# BL702 register map
Vendor: Bouffalo Lab; Series: WiFi BT; File version: 1.0
Registers are 32-bit, read-write, reset 0x0 unless marked. A register's access mark holds for its fields unless they carry their own. Offsets are from the block's base; [hi:lo] are bit positions; {n}, {i} and the like mark numbered series.

## MIX — RF mixed signal registers
Base 0x40001000
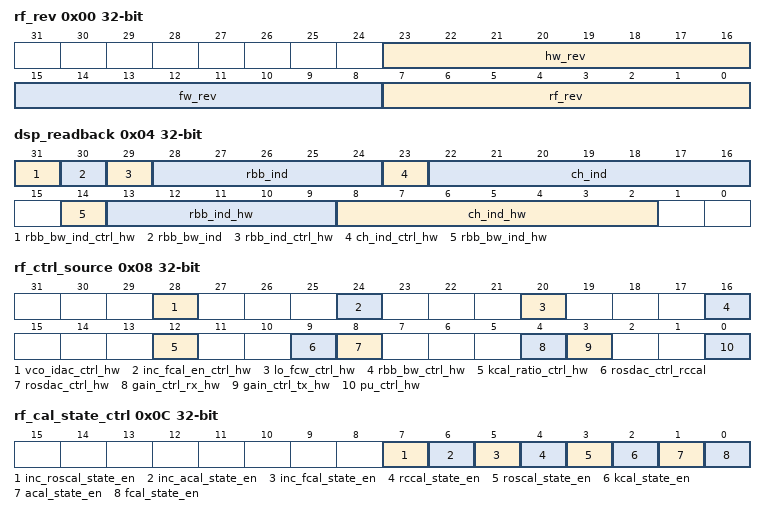
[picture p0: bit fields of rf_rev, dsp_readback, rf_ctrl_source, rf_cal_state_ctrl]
0x00 rf_rev — Silicon revision
  [23:16] hw_rev, [15:8] fw_rev, [7:0] rf_rev
0x04 dsp_readback
  [31] rbb_bw_ind_ctrl_hw, [30] rbb_bw_ind, [29] rbb_ind_ctrl_hw, [28:24] rbb_ind, [23] ch_ind_ctrl_hw, [22:16] ch_ind, [14] rbb_bw_ind_hw, [13:9] rbb_ind_hw, [8:2] ch_ind_hw
0x08 rf_ctrl_source — Control logic switch
  [28] vco_idac_ctrl_hw, [24] inc_fcal_en_ctrl_hw, [20] lo_fcw_ctrl_hw, [16] rbb_bw_ctrl_hw, [12] kcal_ratio_ctrl_hw, [9] rosdac_ctrl_rccal, [8] rosdac_ctrl_hw, [4] gain_ctrl_rx_hw, [3] gain_ctrl_tx_hw, [0] pu_ctrl_hw
0x0C rf_cal_state_ctrl — rf calibration state enable in full cal list
  [7] inc_roscal_state_en, [6] inc_acal_state_en, [5] inc_fcal_state_en, [4] rccal_state_en, [3] roscal_state_en, [2] kcal_state_en, [1] acal_state_en, [0] fcal_state_en
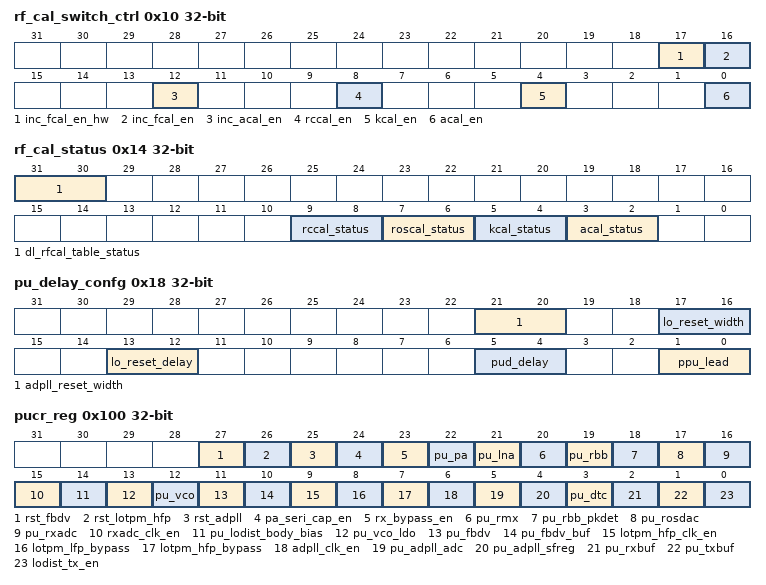
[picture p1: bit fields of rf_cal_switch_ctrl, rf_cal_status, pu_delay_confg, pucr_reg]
0x10 rf_cal_switch_ctrl — Calibration mode register
  [17] inc_fcal_en_hw, [16] inc_fcal_en, [12] inc_acal_en, [8] rccal_en, [4] kcal_en, [0] acal_en
0x14 rf_cal_status
  [31:30] dl_rfcal_table_status, [9:8] rccal_status, [7:6] roscal_status, [5:4] kcal_status, [3:2] acal_status
0x18 pu_delay_confg
  [21:20] adpll_reset_width, [17:16] lo_reset_width, [13:12] lo_reset_delay, [5:4] pud_delay, [1:0] ppu_lead
0x100 pucr_reg — Register control of power up signals
  [27] rst_fbdv, [26] rst_lotpm_hfp, [25] rst_adpll, [24] pa_seri_cap_en, [23] rx_bypass_en, [22] pu_pa, [21] pu_lna, [20] pu_rmx, [19] pu_rbb, [18] pu_rbb_pkdet, [17] pu_rosdac, [16] pu_rxadc, [15] rxadc_clk_en, [14] pu_lodist_body_bias, [13] pu_vco_ldo, [12] pu_vco, [11] pu_fbdv, [10] pu_fbdv_buf, [9] lotpm_hfp_clk_en, [8] lotpm_lfp_bypass, [7] lotpm_hfp_bypass, [6] adpll_clk_en, [5] pu_adpll_adc, [4] pu_adpll_sfreg, [3] pu_dtc, [2] pu_rxbuf, [1] pu_txbuf, [0] lodist_tx_en
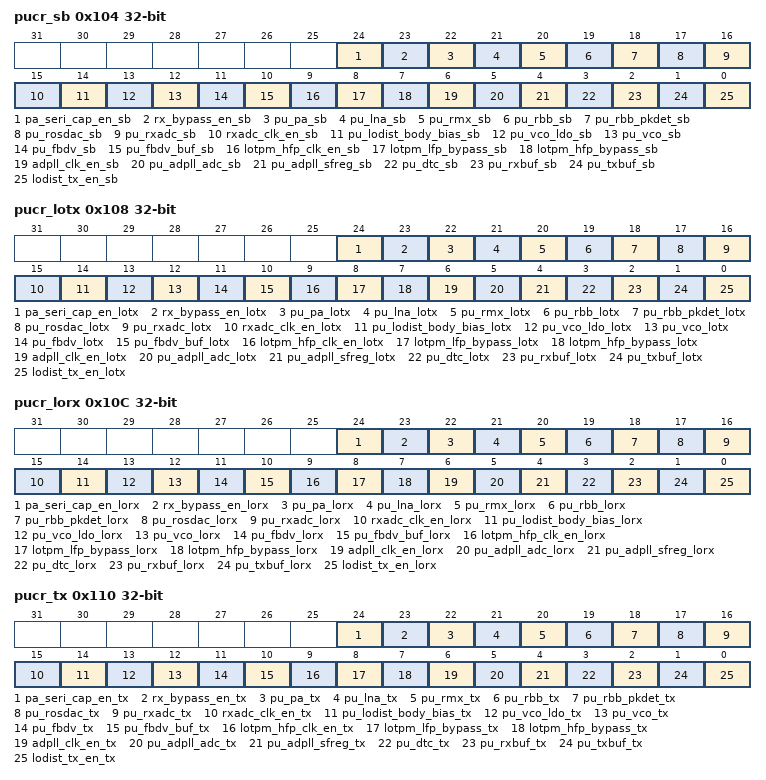
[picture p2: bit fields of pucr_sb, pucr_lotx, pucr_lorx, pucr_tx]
0x104 pucr_sb — Power up setting in SB state
  [24] pa_seri_cap_en_sb, [23] rx_bypass_en_sb, [22] pu_pa_sb, [21] pu_lna_sb, [20] pu_rmx_sb, [19] pu_rbb_sb, [18] pu_rbb_pkdet_sb, [17] pu_rosdac_sb, [16] pu_rxadc_sb, [15] rxadc_clk_en_sb, [14] pu_lodist_body_bias_sb, [13] pu_vco_ldo_sb, [12] pu_vco_sb, [11] pu_fbdv_sb, [10] pu_fbdv_buf_sb, [9] lotpm_hfp_clk_en_sb, [8] lotpm_lfp_bypass_sb, [7] lotpm_hfp_bypass_sb, [6] adpll_clk_en_sb, [5] pu_adpll_adc_sb, [4] pu_adpll_sfreg_sb, [3] pu_dtc_sb, [2] pu_rxbuf_sb, [1] pu_txbuf_sb, [0] lodist_tx_en_sb
0x108 pucr_lotx — Power up in LOTX state
  [24] pa_seri_cap_en_lotx, [23] rx_bypass_en_lotx, [22] pu_pa_lotx, [21] pu_lna_lotx, [20] pu_rmx_lotx, [19] pu_rbb_lotx, [18] pu_rbb_pkdet_lotx, [17] pu_rosdac_lotx, [16] pu_rxadc_lotx, [15] rxadc_clk_en_lotx, [14] pu_lodist_body_bias_lotx, [13] pu_vco_ldo_lotx, [12] pu_vco_lotx, [11] pu_fbdv_lotx, [10] pu_fbdv_buf_lotx, [9] lotpm_hfp_clk_en_lotx, [8] lotpm_lfp_bypass_lotx, [7] lotpm_hfp_bypass_lotx, [6] adpll_clk_en_lotx, [5] pu_adpll_adc_lotx, [4] pu_adpll_sfreg_lotx, [3] pu_dtc_lotx, [2] pu_rxbuf_lotx, [1] pu_txbuf_lotx, [0] lodist_tx_en_lotx
0x10C pucr_lorx — Power up in LORX state
  [24] pa_seri_cap_en_lorx, [23] rx_bypass_en_lorx, [22] pu_pa_lorx, [21] pu_lna_lorx, [20] pu_rmx_lorx, [19] pu_rbb_lorx, [18] pu_rbb_pkdet_lorx, [17] pu_rosdac_lorx, [16] pu_rxadc_lorx, [15] rxadc_clk_en_lorx, [14] pu_lodist_body_bias_lorx, [13] pu_vco_ldo_lorx, [12] pu_vco_lorx, [11] pu_fbdv_lorx, [10] pu_fbdv_buf_lorx, [9] lotpm_hfp_clk_en_lorx, [8] lotpm_lfp_bypass_lorx, [7] lotpm_hfp_bypass_lorx, [6] adpll_clk_en_lorx, [5] pu_adpll_adc_lorx, [4] pu_adpll_sfreg_lorx, [3] pu_dtc_lorx, [2] pu_rxbuf_lorx, [1] pu_txbuf_lorx, [0] lodist_tx_en_lorx
0x110 pucr_tx — Power up in TX state
  [24] pa_seri_cap_en_tx, [23] rx_bypass_en_tx, [22] pu_pa_tx, [21] pu_lna_tx, [20] pu_rmx_tx, [19] pu_rbb_tx, [18] pu_rbb_pkdet_tx, [17] pu_rosdac_tx, [16] pu_rxadc_tx, [15] rxadc_clk_en_tx, [14] pu_lodist_body_bias_tx, [13] pu_vco_ldo_tx, [12] pu_vco_tx, [11] pu_fbdv_tx, [10] pu_fbdv_buf_tx, [9] lotpm_hfp_clk_en_tx, [8] lotpm_lfp_bypass_tx, [7] lotpm_hfp_bypass_tx, [6] adpll_clk_en_tx, [5] pu_adpll_adc_tx, [4] pu_adpll_sfreg_tx, [3] pu_dtc_tx, [2] pu_rxbuf_tx, [1] pu_txbuf_tx, [0] lodist_tx_en_tx
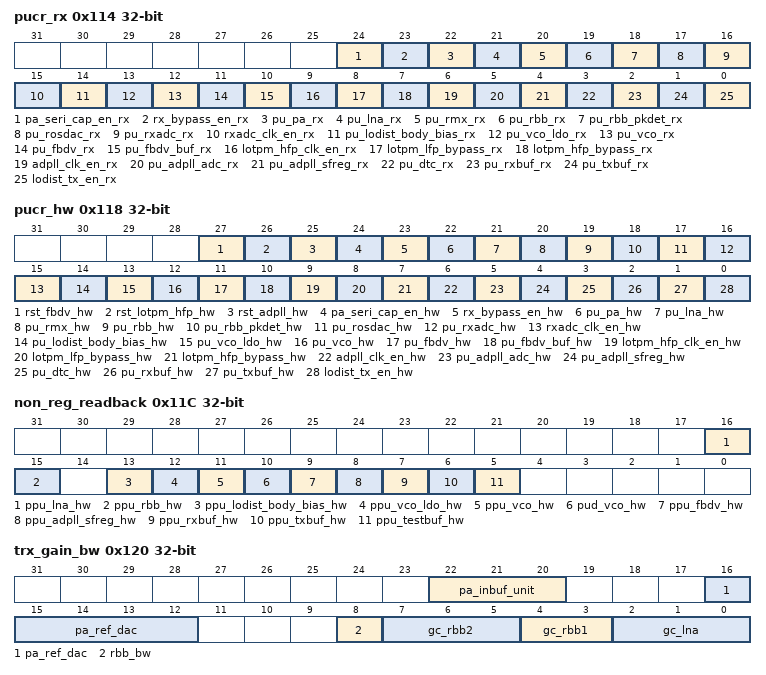
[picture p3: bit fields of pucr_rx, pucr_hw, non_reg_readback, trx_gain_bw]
0x114 pucr_rx — Power up in RX state
  [24] pa_seri_cap_en_rx, [23] rx_bypass_en_rx, [22] pu_pa_rx, [21] pu_lna_rx, [20] pu_rmx_rx, [19] pu_rbb_rx, [18] pu_rbb_pkdet_rx, [17] pu_rosdac_rx, [16] pu_rxadc_rx, [15] rxadc_clk_en_rx, [14] pu_lodist_body_bias_rx, [13] pu_vco_ldo_rx, [12] pu_vco_rx, [11] pu_fbdv_rx, [10] pu_fbdv_buf_rx, [9] lotpm_hfp_clk_en_rx, [8] lotpm_lfp_bypass_rx, [7] lotpm_hfp_bypass_rx, [6] adpll_clk_en_rx, [5] pu_adpll_adc_rx, [4] pu_adpll_sfreg_rx, [3] pu_dtc_rx, [2] pu_rxbuf_rx, [1] pu_txbuf_rx, [0] lodist_tx_en_rx
0x118 pucr_hw — Hardware read back of power up signals
  [27] rst_fbdv_hw, [26] rst_lotpm_hfp_hw, [25] rst_adpll_hw, [24] pa_seri_cap_en_hw, [23] rx_bypass_en_hw, [22] pu_pa_hw, [21] pu_lna_hw, [20] pu_rmx_hw, [19] pu_rbb_hw, [18] pu_rbb_pkdet_hw, [17] pu_rosdac_hw, [16] pu_rxadc_hw, [15] rxadc_clk_en_hw, [14] pu_lodist_body_bias_hw, [13] pu_vco_ldo_hw, [12] pu_vco_hw, [11] pu_fbdv_hw, [10] pu_fbdv_buf_hw, [9] lotpm_hfp_clk_en_hw, [8] lotpm_lfp_bypass_hw, [7] lotpm_hfp_bypass_hw, [6] adpll_clk_en_hw, [5] pu_adpll_adc_hw, [4] pu_adpll_sfreg_hw, [3] pu_dtc_hw, [2] pu_rxbuf_hw, [1] pu_txbuf_hw, [0] lodist_tx_en_hw
0x11C non_reg_readback
  [16] ppu_lna_hw, [15] ppu_rbb_hw, [13] ppu_lodist_body_bias_hw, [12] ppu_vco_ldo_hw, [11] ppu_vco_hw, [10] pud_vco_hw, [9] ppu_fbdv_hw, [8] ppu_adpll_sfreg_hw, [7] ppu_rxbuf_hw, [6] ppu_txbuf_hw, [5] ppu_testbuf_hw
0x120 trx_gain_bw — Register control of TX/RX gain
  [22:20] pa_inbuf_unit, [16:12] pa_ref_dac, [8] rbb_bw, [7:5] gc_rbb2, [4:3] gc_rbb1, [2:0] gc_lna
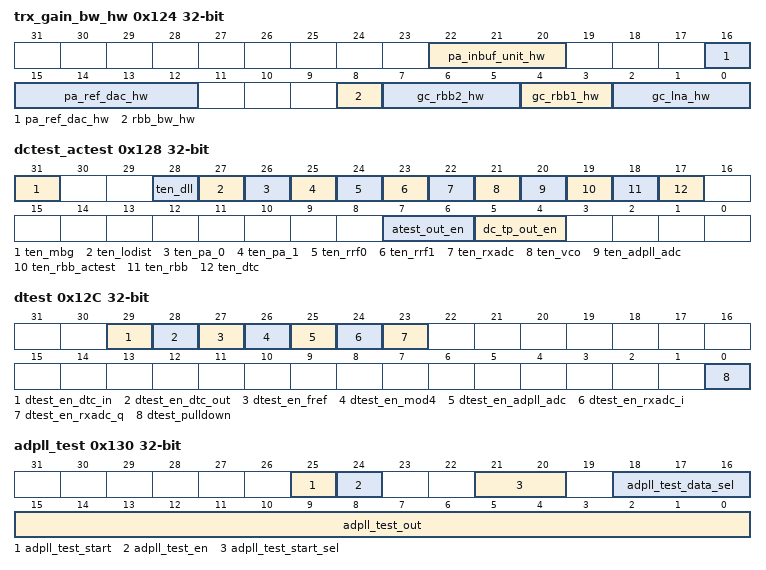
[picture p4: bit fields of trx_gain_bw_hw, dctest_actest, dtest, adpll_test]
0x124 trx_gain_bw_hw — Hardware read back of TX/RX gain
  [22:20] pa_inbuf_unit_hw, [16:12] pa_ref_dac_hw, [8] rbb_bw_hw, [7:5] gc_rbb2_hw, [4:3] gc_rbb1_hw, [2:0] gc_lna_hw
0x128 dctest_actest — DC Test register 0
  [31] ten_mbg, [28] ten_dll, [27] ten_lodist, [26] ten_pa_0, [25] ten_pa_1, [24] ten_rrf0, [23] ten_rrf1, [22] ten_rxadc, [21] ten_vco, [20] ten_adpll_adc, [19] ten_rbb_actest, [18] ten_rbb, [17] ten_dtc, [7:6] atest_out_en, [5:4] dc_tp_out_en
0x12C dtest — LO Bias Mode registers
  [29] dtest_en_dtc_in, [28] dtest_en_dtc_out, [27] dtest_en_fref, [26] dtest_en_mod4, [25] dtest_en_adpll_adc, [24] dtest_en_rxadc_i, [23] dtest_en_rxadc_q, [0] dtest_pulldown
0x130 adpll_test
  [25] adpll_test_start, [24] adpll_test_en, [21:20] adpll_test_start_sel, [18:16] adpll_test_data_sel, [15:0] adpll_test_out
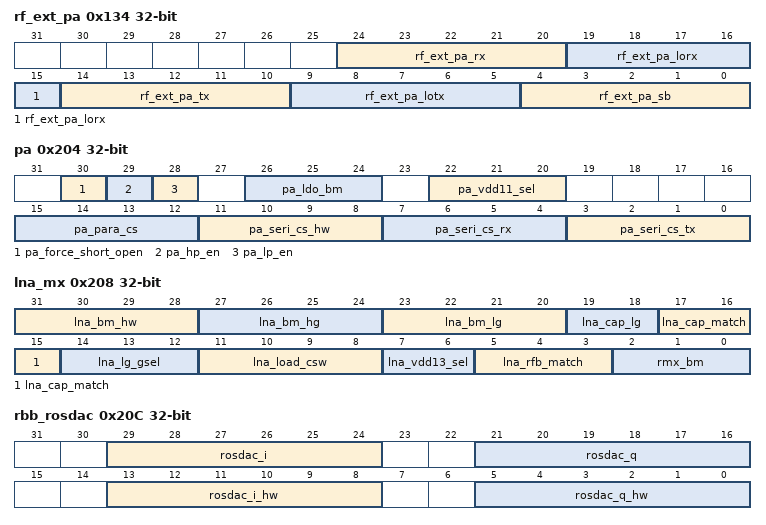
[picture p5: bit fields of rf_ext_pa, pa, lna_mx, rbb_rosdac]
0x134 rf_ext_pa
  [24:20] rf_ext_pa_rx, [19:15] rf_ext_pa_lorx, [14:10] rf_ext_pa_tx, [9:5] rf_ext_pa_lotx, [4:0] rf_ext_pa_sb
0x200 cip_ldo15
  [1:0] vg11_sel
0x204 pa
  [30] pa_force_short_open, [29] pa_hp_en, [28] pa_lp_en, [26:24] pa_ldo_bm, [22:20] pa_vdd11_sel, [15:12] pa_para_cs, [11:8] pa_seri_cs_hw, [7:4] pa_seri_cs_rx, [3:0] pa_seri_cs_tx
0x208 lna_mx — LNA mixer register
  [31:28] lna_bm_hw, [27:24] lna_bm_hg, [23:20] lna_bm_lg, [19:18] lna_cap_lg, [17:15] lna_cap_match, [14:12] lna_lg_gsel, [11:8] lna_load_csw, [7:6] lna_vdd13_sel, [5:3] lna_rfb_match, [2:0] rmx_bm
0x20C rbb_rosdac
  [29:24] rosdac_i, [21:16] rosdac_q, [13:8] rosdac_i_hw, [5:0] rosdac_q_hw
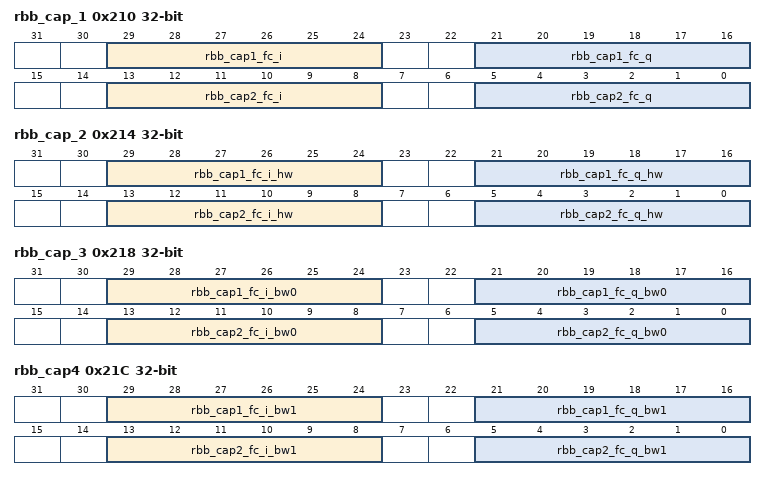
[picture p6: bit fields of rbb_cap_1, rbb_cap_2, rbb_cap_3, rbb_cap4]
0x210 rbb_cap_1
  [29:24] rbb_cap1_fc_i, [21:16] rbb_cap1_fc_q, [13:8] rbb_cap2_fc_i, [5:0] rbb_cap2_fc_q
0x214 rbb_cap_2
  [29:24] rbb_cap1_fc_i_hw, [21:16] rbb_cap1_fc_q_hw, [13:8] rbb_cap2_fc_i_hw, [5:0] rbb_cap2_fc_q_hw
0x218 rbb_cap_3
  [29:24] rbb_cap1_fc_i_bw0, [21:16] rbb_cap1_fc_q_bw0, [13:8] rbb_cap2_fc_i_bw0, [5:0] rbb_cap2_fc_q_bw0
0x21C rbb_cap4
  [29:24] rbb_cap1_fc_i_bw1, [21:16] rbb_cap1_fc_q_bw1, [13:8] rbb_cap2_fc_i_bw1, [5:0] rbb_cap2_fc_q_bw1
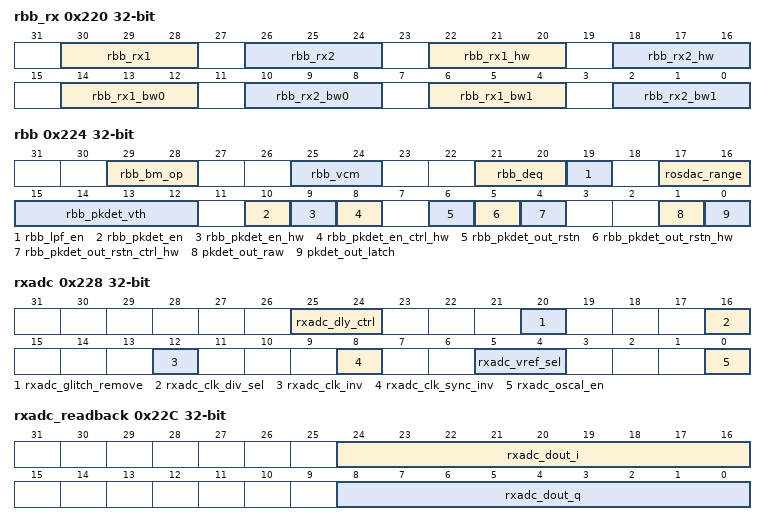
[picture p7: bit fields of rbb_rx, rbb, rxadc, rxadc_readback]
0x220 rbb_rx
  [30:28] rbb_rx1, [26:24] rbb_rx2, [22:20] rbb_rx1_hw, [18:16] rbb_rx2_hw, [14:12] rbb_rx1_bw0, [10:8] rbb_rx2_bw0, [6:4] rbb_rx1_bw1, [2:0] rbb_rx2_bw1
0x224 rbb
  [29:28] rbb_bm_op, [25:24] rbb_vcm, [21:20] rbb_deq, [19] rbb_lpf_en, [17:16] rosdac_range, [15:12] rbb_pkdet_vth, [10] rbb_pkdet_en, [9] rbb_pkdet_en_hw, [8] rbb_pkdet_en_ctrl_hw, [6] rbb_pkdet_out_rstn, [5] rbb_pkdet_out_rstn_hw, [4] rbb_pkdet_out_rstn_ctrl_hw, [1] pkdet_out_raw, [0] pkdet_out_latch
0x228 rxadc
  [25:24] rxadc_dly_ctrl, [20] rxadc_glitch_remove, [16] rxadc_clk_div_sel, [12] rxadc_clk_inv, [8] rxadc_clk_sync_inv, [5:4] rxadc_vref_sel, [0] rxadc_oscal_en
0x22C rxadc_readback
  [24:16] rxadc_dout_i, [8:0] rxadc_dout_q
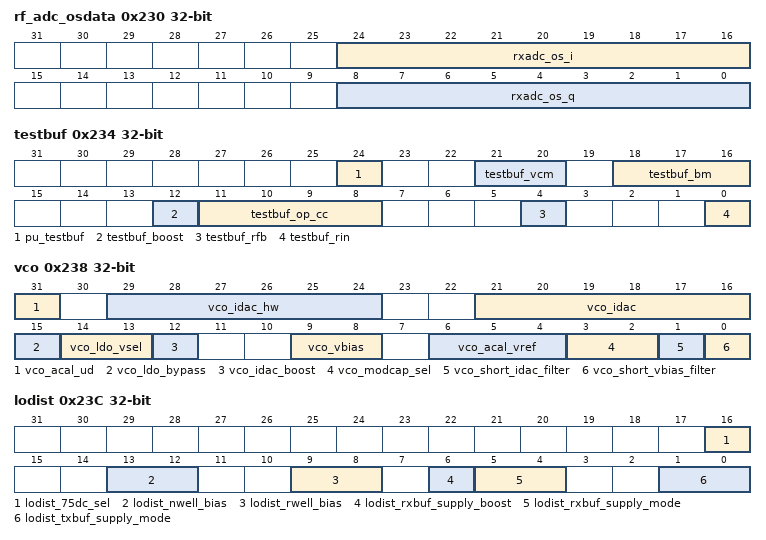
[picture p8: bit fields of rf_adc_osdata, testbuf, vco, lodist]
0x230 rf_adc_osdata
  [24:16] rxadc_os_i, [8:0] rxadc_os_q
0x234 testbuf
  [24] pu_testbuf, [21:20] testbuf_vcm, [18:16] testbuf_bm, [12] testbuf_boost, [11:8] testbuf_op_cc, [4] testbuf_rfb, [0] testbuf_rin
0x238 vco
  [31] vco_acal_ud, [29:24] vco_idac_hw, [21:16] vco_idac, [15] vco_ldo_bypass, [14:13] vco_ldo_vsel, [12] vco_idac_boost, [9:8] vco_vbias, [6:4] vco_acal_vref, [3:2] vco_modcap_sel, [1] vco_short_idac_filter, [0] vco_short_vbias_filter
0x23C lodist
  [16] lodist_75dc_sel, [13:12] lodist_nwell_bias, [9:8] lodist_rwell_bias, [6] lodist_rxbuf_supply_boost, [5:4] lodist_rxbuf_supply_mode, [1:0] lodist_txbuf_supply_mode
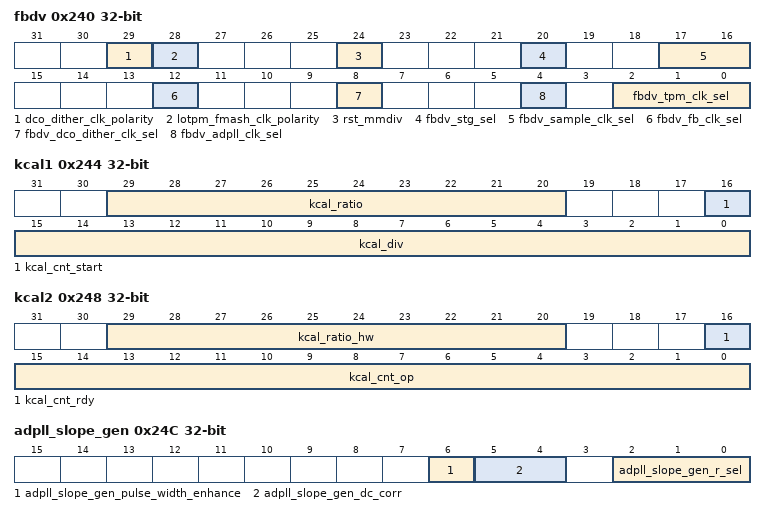
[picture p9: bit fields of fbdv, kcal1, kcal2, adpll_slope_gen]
0x240 fbdv
  [29] dco_dither_clk_polarity, [28] lotpm_fmash_clk_polarity, [24] rst_mmdiv, [20] fbdv_stg_sel, [17:16] fbdv_sample_clk_sel, [12] fbdv_fb_clk_sel, [8] fbdv_dco_dither_clk_sel, [4] fbdv_adpll_clk_sel, [2:0] fbdv_tpm_clk_sel
0x244 kcal1
  [29:20] kcal_ratio, [16] kcal_cnt_start, [15:0] kcal_div
0x248 kcal2
  [29:20] kcal_ratio_hw, [16] kcal_cnt_rdy, [15:0] kcal_cnt_op
0x24C adpll_slope_gen
  [6] adpll_slope_gen_pulse_width_enhance, [5:4] adpll_slope_gen_dc_corr, [2:0] adpll_slope_gen_r_sel
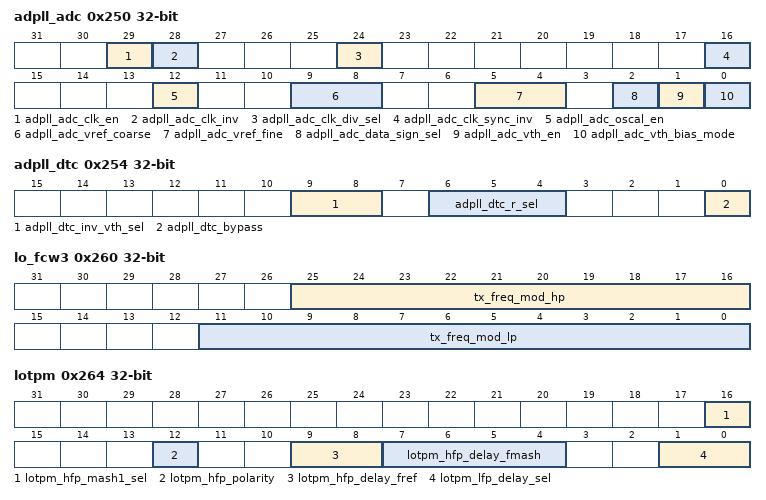
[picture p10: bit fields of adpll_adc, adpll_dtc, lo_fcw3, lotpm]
0x250 adpll_adc
  [29] adpll_adc_clk_en, [28] adpll_adc_clk_inv, [24] adpll_adc_clk_div_sel, [16] adpll_adc_clk_sync_inv, [12] adpll_adc_oscal_en, [9:8] adpll_adc_vref_coarse, [5:4] adpll_adc_vref_fine, [2] adpll_adc_data_sign_sel, [1] adpll_adc_vth_en, [0] adpll_adc_vth_bias_mode
0x254 adpll_dtc
  [9:8] adpll_dtc_inv_vth_sel, [6:4] adpll_dtc_r_sel, [0] adpll_dtc_bypass
0x258 lo_fc_config1
  [24:0] lo_fcw
0x25C lo_fcw_config2
  [24:0] lo_fcw_hw
0x260 lo_fcw3
  [25:16] tx_freq_mod_hp, [11:0] tx_freq_mod_lp
0x264 lotpm
  [16] lotpm_hfp_mash1_sel, [12] lotpm_hfp_polarity, [9:8] lotpm_hfp_delay_fref, [7:4] lotpm_hfp_delay_fmash, [1:0] lotpm_lfp_delay_sel
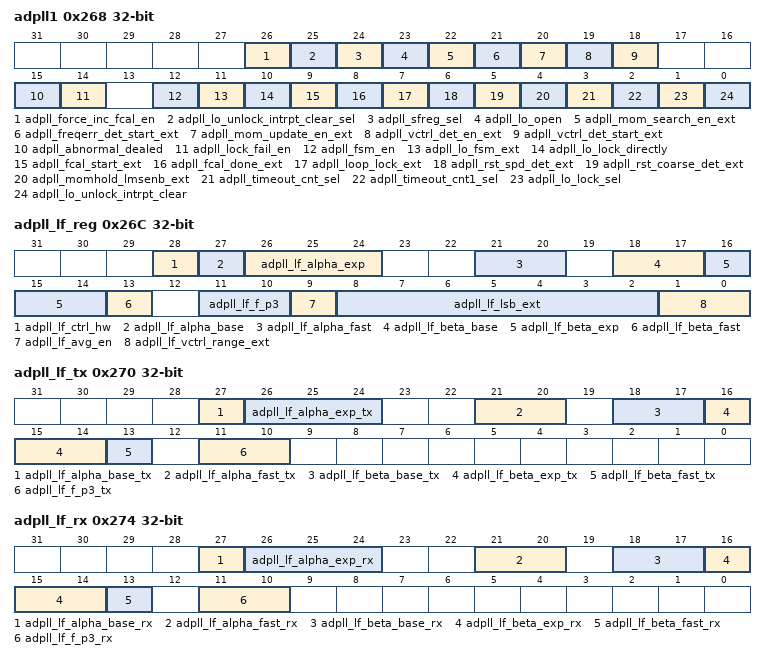
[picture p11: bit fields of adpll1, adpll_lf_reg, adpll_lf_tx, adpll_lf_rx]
0x268 adpll1
  [26] adpll_force_inc_fcal_en, [25] adpll_lo_unlock_intrpt_clear_sel, [24] adpll_sfreg_sel, [23] adpll_lo_open, [22] adpll_mom_search_en_ext, [21] adpll_freqerr_det_start_ext, [20] adpll_mom_update_en_ext, [19] adpll_vctrl_det_en_ext, [18] adpll_vctrl_det_start_ext, [15] adpll_abnormal_dealed, [14] adpll_lock_fail_en, [12] adpll_fsm_en, [11] adpll_lo_fsm_ext, [10] adpll_lo_lock_directly, [9] adpll_fcal_start_ext, [8] adpll_fcal_done_ext, [7] adpll_loop_lock_ext, [6] adpll_rst_spd_det_ext, [5] adpll_rst_coarse_det_ext, [4] adpll_momhold_lmsenb_ext, [3] adpll_timeout_cnt_sel, [2] adpll_timeout_cnt1_sel, [1] adpll_lo_lock_sel, [0] adpll_lo_unlock_intrpt_clear
0x26C adpll_lf_reg
  [28] adpll_lf_ctrl_hw, [27] adpll_lf_alpha_base, [26:24] adpll_lf_alpha_exp, [21:20] adpll_lf_alpha_fast, [18:17] adpll_lf_beta_base, [16:14] adpll_lf_beta_exp, [13] adpll_lf_beta_fast, [11:10] adpll_lf_f_p3, [9] adpll_lf_avg_en, [8:2] adpll_lf_lsb_ext, [1:0] adpll_lf_vctrl_range_ext
0x270 adpll_lf_tx
  [27] adpll_lf_alpha_base_tx, [26:24] adpll_lf_alpha_exp_tx, [21:20] adpll_lf_alpha_fast_tx, [18:17] adpll_lf_beta_base_tx, [16:14] adpll_lf_beta_exp_tx, [13] adpll_lf_beta_fast_tx, [11:10] adpll_lf_f_p3_tx
0x274 adpll_lf_rx
  [27] adpll_lf_alpha_base_rx, [26:24] adpll_lf_alpha_exp_rx, [21:20] adpll_lf_alpha_fast_rx, [18:17] adpll_lf_beta_base_rx, [16:14] adpll_lf_beta_exp_rx, [13] adpll_lf_beta_fast_rx, [11:10] adpll_lf_f_p3_rx
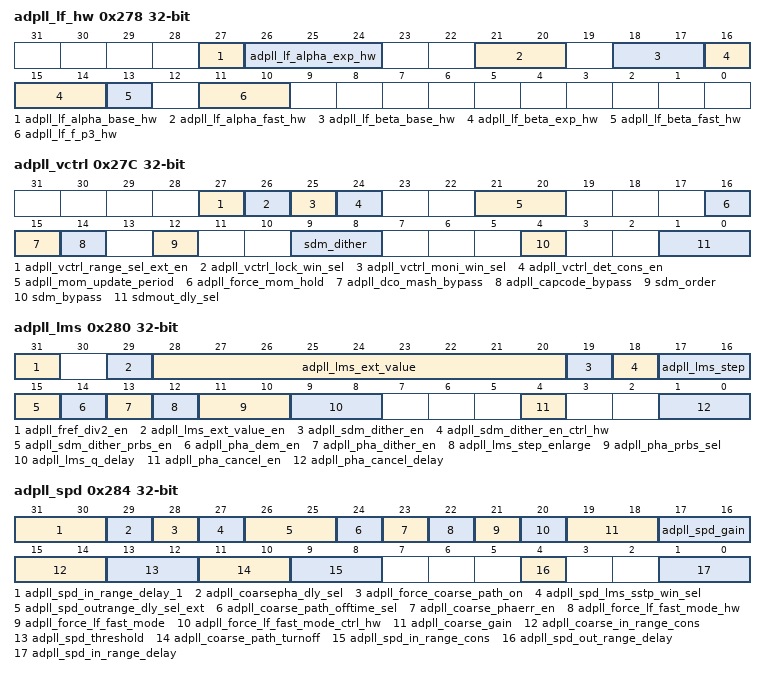
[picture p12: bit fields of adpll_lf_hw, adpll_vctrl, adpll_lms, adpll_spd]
0x278 adpll_lf_hw
  [27] adpll_lf_alpha_base_hw, [26:24] adpll_lf_alpha_exp_hw, [21:20] adpll_lf_alpha_fast_hw, [18:17] adpll_lf_beta_base_hw, [16:14] adpll_lf_beta_exp_hw, [13] adpll_lf_beta_fast_hw, [11:10] adpll_lf_f_p3_hw
0x27C adpll_vctrl
  [27] adpll_vctrl_range_sel_ext_en, [26] adpll_vctrl_lock_win_sel, [25] adpll_vctrl_moni_win_sel, [24] adpll_vctrl_det_cons_en, [21:20] adpll_mom_update_period, [16] adpll_force_mom_hold, [15] adpll_dco_mash_bypass, [14] adpll_capcode_bypass, [12] sdm_order, [9:8] sdm_dither, [4] sdm_bypass, [1:0] sdmout_dly_sel
0x280 adpll_lms
  [31] adpll_fref_div2_en, [29] adpll_lms_ext_value_en, [28:20] adpll_lms_ext_value, [19] adpll_sdm_dither_en, [18] adpll_sdm_dither_en_ctrl_hw, [17:16] adpll_lms_step, [15] adpll_sdm_dither_prbs_en, [14] adpll_pha_dem_en, [13] adpll_pha_dither_en, [12] adpll_lms_step_enlarge, [11:10] adpll_pha_prbs_sel, [9:8] adpll_lms_q_delay, [4] adpll_pha_cancel_en, [1:0] adpll_pha_cancel_delay
0x284 adpll_spd
  [31:30] adpll_spd_in_range_delay_1, [29] adpll_coarsepha_dly_sel, [28] adpll_force_coarse_path_on, [27] adpll_spd_lms_sstp_win_sel, [26:25] adpll_spd_outrange_dly_sel_ext, [24] adpll_coarse_path_offtime_sel, [23] adpll_coarse_phaerr_en, [22] adpll_force_lf_fast_mode_hw, [21] adpll_force_lf_fast_mode, [20] adpll_force_lf_fast_mode_ctrl_hw, [19:18] adpll_coarse_gain, [17:16] adpll_spd_gain, [15:14] adpll_coarse_in_range_cons, [13:12] adpll_spd_threshold, [11:10] adpll_coarse_path_turnoff, [9:8] adpll_spd_in_range_cons, [4] adpll_spd_out_range_delay, [1:0] adpll_spd_in_range_delay
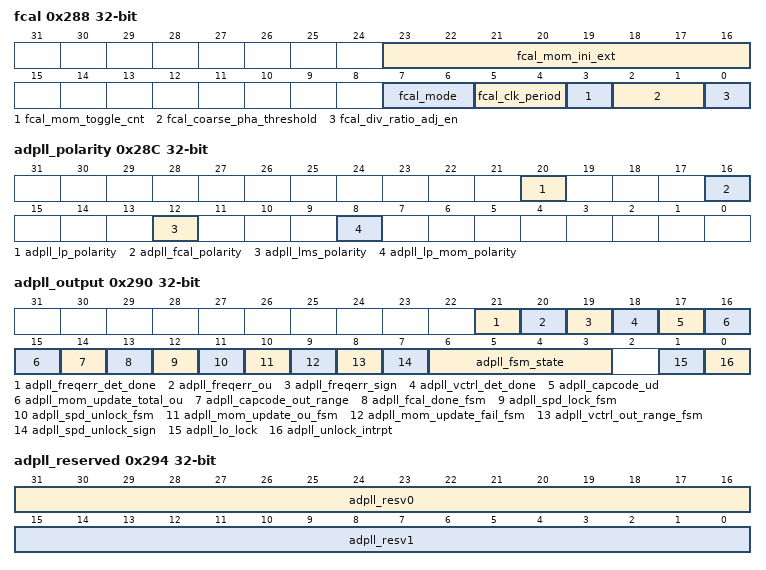
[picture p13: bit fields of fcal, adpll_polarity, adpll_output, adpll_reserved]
0x288 fcal
  [23:16] fcal_mom_ini_ext, [7:6] fcal_mode, [5:4] fcal_clk_period, [3] fcal_mom_toggle_cnt, [2:1] fcal_coarse_pha_threshold, [0] fcal_div_ratio_adj_en
0x28C adpll_polarity
  [20] adpll_lp_polarity, [16] adpll_fcal_polarity, [12] adpll_lms_polarity, [8] adpll_lp_mom_polarity
0x290 adpll_output
  [21] adpll_freqerr_det_done, [20] adpll_freqerr_ou, [19] adpll_freqerr_sign, [18] adpll_vctrl_det_done, [17] adpll_capcode_ud, [16:15] adpll_mom_update_total_ou, [14] adpll_capcode_out_range, [13] adpll_fcal_done_fsm, [12] adpll_spd_lock_fsm, [11] adpll_spd_unlock_fsm, [10] adpll_mom_update_ou_fsm, [9] adpll_mom_update_fail_fsm, [8] adpll_vctrl_out_range_fsm, [7] adpll_spd_unlock_sign, [6:3] adpll_fsm_state, [1] adpll_lo_lock, [0] adpll_unlock_intrpt
0x294 adpll_reserved
  [31:16] adpll_resv0, [15:0] adpll_resv1
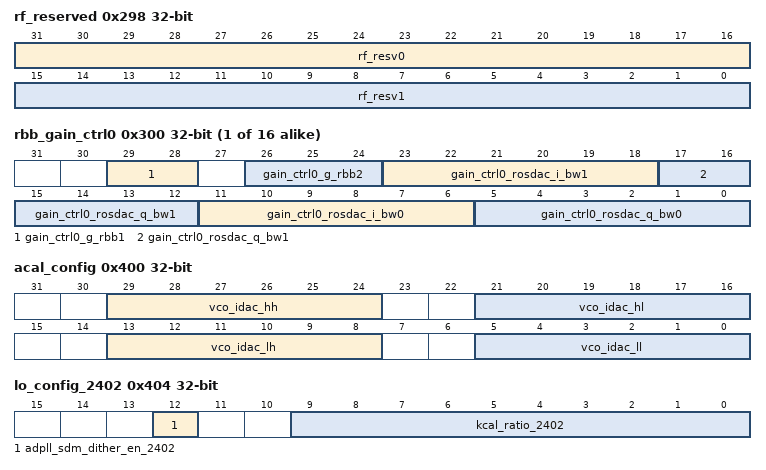
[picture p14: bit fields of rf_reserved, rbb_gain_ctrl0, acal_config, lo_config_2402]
0x298 rf_reserved
  [31:16] rf_resv0, [15:0] rf_resv1
0x29C rf_reserved_2
  [31:0] rf_resv
{0x300+4i} rbb_gain_ctrl{i} (i=0..15)
  [29:28] gain_ctrl{i}_g_rbb1, [26:24] gain_ctrl{i}_g_rbb2, [23:18] gain_ctrl{i}_rosdac_i_bw1, [17:12] gain_ctrl{i}_rosdac_q_bw1, [11:6] gain_ctrl{i}_rosdac_i_bw0, [5:0] gain_ctrl{i}_rosdac_q_bw0
0x3FC rssi
  [15:8] rssi — RSSI of received frame, RSSI in dBm = 5 - rssi_bits
  [23:8] crc
0x400 acal_config
  [29:24] vco_idac_hh, [21:16] vco_idac_hl, [13:8] vco_idac_lh, [5:0] vco_idac_ll
0x404 lo_config_2402
  [12] adpll_sdm_dither_en_2402, [9:0] kcal_ratio_2402
0x408 lo_config_2404
  [12] adpll_sdm_dither_en_2404, [9:0] kcal_ratio_2404
0x40C lo_config_2406
  [12] adpll_sdm_dither_en_2406, [9:0] kcal_ratio_2406
0x410 lo_config_2408
  [12] adpll_sdm_dither_en_2408, [9:0] kcal_ratio_2408
0x414 lo_config_2410
  [12] adpll_sdm_dither_en_2410, [9:0] kcal_ratio_2410
0x418 lo_config_2412
  [12] adpll_sdm_dither_en_2412, [9:0] kcal_ratio_2412
0x41C lo_config_2414
  [12] adpll_sdm_dither_en_2414, [9:0] kcal_ratio_2414
0x420 lo_config_2416
  [12] adpll_sdm_dither_en_2416, [9:0] kcal_ratio_2416
0x424 lo_config_2418
  [12] adpll_sdm_dither_en_2418, [9:0] kcal_ratio_2418
0x428 lo_config_2420
  [12] adpll_sdm_dither_en_2420, [9:0] kcal_ratio_2420
0x42C lo_config_2422
  [12] adpll_sdm_dither_en_2422, [9:0] kcal_ratio_2422
0x430 lo_config_2424
  [12] adpll_sdm_dither_en_2424, [9:0] kcal_ratio_2424
0x434 lo_config_2426
  [12] adpll_sdm_dither_en_2426, [9:0] kcal_ratio_2426
0x438 lo_config_2428
  [12] adpll_sdm_dither_en_2428, [9:0] kcal_ratio_2428
0x43C lo_config_2430
  [12] adpll_sdm_dither_en_2430, [9:0] kcal_ratio_2430
0x440 lo_config_2432
  [12] adpll_sdm_dither_en_2432, [9:0] kcal_ratio_2432
0x444 lo_config_2434
  [12] adpll_sdm_dither_en_2434, [9:0] kcal_ratio_2434
0x448 lo_config_2436
  [12] adpll_sdm_dither_en_2436, [9:0] kcal_ratio_2436
0x44C lo_config_2438
  [12] adpll_sdm_dither_en_2438, [9:0] kcal_ratio_2438
0x450 lo_config_2440
  [12] adpll_sdm_dither_en_2440, [9:0] kcal_ratio_2440
0x454 lo_config_2442
  [12] adpll_sdm_dither_en_2442, [9:0] kcal_ratio_2442
0x458 lo_config_2444
  [12] adpll_sdm_dither_en_2444, [9:0] kcal_ratio_2444
0x45C lo_config_2446
  [12] adpll_sdm_dither_en_2446, [9:0] kcal_ratio_2446
0x460 lo_config_2448
  [12] adpll_sdm_dither_en_2448, [9:0] kcal_ratio_2448
0x464 lo_config_2450
  [12] adpll_sdm_dither_en_2450, [9:0] kcal_ratio_2450
0x468 lo_config_2452
  [12] adpll_sdm_dither_en_2452, [9:0] kcal_ratio_2452
0x46C lo_config_2454
  [12] adpll_sdm_dither_en_2454, [9:0] kcal_ratio_2454
0x470 lo_config_2456
  [12] adpll_sdm_dither_en_2456, [9:0] kcal_ratio_2456
0x474 lo_config_2458
  [12] adpll_sdm_dither_en_2458, [9:0] kcal_ratio_2458
0x478 lo_config_2460
  [12] adpll_sdm_dither_en_2460, [9:0] kcal_ratio_2460
0x47C lo_config_2462
  [12] adpll_sdm_dither_en_2462, [9:0] kcal_ratio_2462
0x480 lo_config_2464
  [12] adpll_sdm_dither_en_2464, [9:0] kcal_ratio_2464
0x484 lo_config_2466
  [12] adpll_sdm_dither_en_2466, [9:0] kcal_ratio_2466
0x488 lo_config_2468
  [12] adpll_sdm_dither_en_2468, [9:0] kcal_ratio_2468
0x48C lo_config_2470
  [12] adpll_sdm_dither_en_2470, [9:0] kcal_ratio_2470
0x490 lo_config_2472
  [12] adpll_sdm_dither_en_2472, [9:0] kcal_ratio_2472
0x494 lo_config_2474
  [12] adpll_sdm_dither_en_2474, [9:0] kcal_ratio_2474
0x498 lo_config_2476
  [12] adpll_sdm_dither_en_2476, [9:0] kcal_ratio_2476
0x49C lo_config_2478
  [12] adpll_sdm_dither_en_2478, [9:0] kcal_ratio_2478
0x4A0 lo_config_2480
  [12] adpll_sdm_dither_en_2480, [9:0] kcal_ratio_2480
0x4A4 lo_config_2405
  [12] adpll_sdm_dither_en_2405, [9:0] kcal_ratio_2405
0x4A8 lo_config_2415
  [12] adpll_sdm_dither_en_2415, [9:0] kcal_ratio_2415
0x4AC lo_config_2425
  [12] adpll_sdm_dither_en_2425, [9:0] kcal_ratio_2425
0x4B0 lo_config_2435
  [12] adpll_sdm_dither_en_2435, [9:0] kcal_ratio_2435
0x4B4 lo_config_2445
  [12] adpll_sdm_dither_en_2445, [9:0] kcal_ratio_2445
0x4B8 lo_config_2455
  [12] adpll_sdm_dither_en_2455, [9:0] kcal_ratio_2455
0x4BC lo_config_2465
  [12] adpll_sdm_dither_en_2465, [9:0] kcal_ratio_2465
0x4C0 lo_config_2475
  [12] adpll_sdm_dither_en_2475, [9:0] kcal_ratio_2475
0x500 dg_testbus_0
  [31:0] rf_testbus_read
0x504 dg_testbus_1
  [3:0] rf_testbus_sel
0x508 dg_ppud_0
  [30] ppud_manaual_en, [29:25] ppud_cnt1, [24:16] ppud_cnt2
0x50C rf_top
  [31] rf_tx_en_src, [30] rf_tx_en_4s, [29] rf_rx_en_src, [28] rf_rx_en_4s, [26] rf_rx_mode_4s_en, [25:24] rf_rx_mode_4s, [23:22] rf_rx_mode_hw, [21:16] rf_mac_lo_time_offset, [2] rfckg_afifo_tx_inv, [1] rfckg_afifo_rxadc_inv, [0] rfckg_afifo_adpll_inv
0x510 rf_fsm
  [31:26] rf_fsm_afifo_dly_time, [25] rf_fsm_tx_afifo_4s_en, [24] rf_fsm_tx_afifo_4s, [23] rf_fsm_rx_afifo_4s_en, [22] rf_fsm_rx_afifo_4s, [21] rf_fsm_en, [20] rf_fsm_st_4s_en, [18:16] rf_fsm_st_4s, [14:12] rf_fsm_state, [11:0] rf_fsm_lo_time
0x514 rf_singen_0
  [31] singen_en, [30:29] singen_clkdiv_n, [28] singen_unsign_en, [25:16] singen_inc_step0, [9:0] singen_inc_step1
0x518 rf_singen_1
  [31:28] singen_mode_i, [25:16] singen_clkdiv_i, [15:12] singen_mode_q, [9:0] singen_clkdiv_q
0x51C rf_singen_2
  [31:22] singen_start_addr0_i, [21:12] singen_start_addr1_i, [10:0] singen_gain_i
0x520 rf_singen_3
  [31:22] singen_start_addr0_q, [21:12] singen_start_addr1_q, [10:0] singen_gain_q
0x524 rf_singen_4
  [28] singen_fix_en_i, [27:16] singen_fix_i, [12] singen_fix_en_q, [11:0] singen_fix_q
0x528 rf_sram_ctrl0
  [31:16] rf_sram_done_cnt, [5:4] rf_sram_mode, [3] rf_sram_sts_clr, [2] rf_sram_loop_en, [1] rf_sram_en, [0] rf_sram_done
0x52C rf_sram_ctrl1
  [31:16] rf_sram_addr_start, [15:0] rf_sram_addr_end
0x530 rf_sram_ctrl2
  [31:0] rf_sram_sts
0x534 rf_test_mode
  [30] rf_test_mode_en, [29] dacout_4s_sram_en, [28] dacout_4s_en, [27:16] dacout_4s, [11:0] dacout_hw
0x538 rf_rx_pulse_filter
  [21] pf_en_i, [20] pf_en_q, [18:10] pf_th1, [8:0] pf_th2
